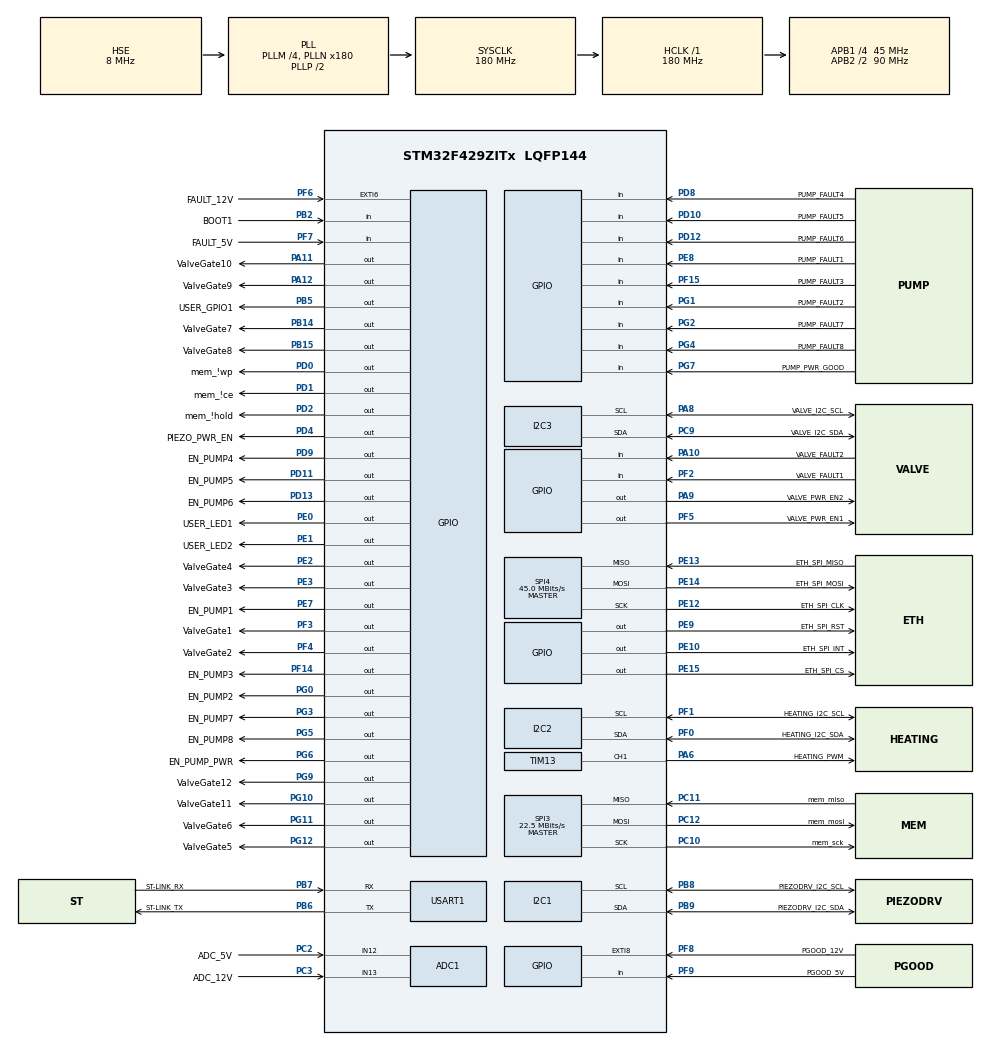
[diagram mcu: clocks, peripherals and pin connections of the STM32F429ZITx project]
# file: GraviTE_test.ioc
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ADC1.Channel-3\#ChannelRegularConversion=ADC_CHANNEL_TEMPSENSOR
ADC1.Channel-4\#ChannelRegularConversion=ADC_CHANNEL_12
ADC1.Channel-5\#ChannelRegularConversion=ADC_CHANNEL_12
ADC1.ContinuousConvMode=ENABLE
ADC1.NbrOfConversion=3
ADC1.NbrOfConversionFlag=1
ADC1.Rank-3\#ChannelRegularConversion=1
ADC1.Rank-4\#ChannelRegularConversion=2
ADC1.Rank-5\#ChannelRegularConversion=3
ADC1.SamplingTime-3\#ChannelRegularConversion=ADC_SAMPLETIME_3CYCLES
ADC1.SamplingTime-4\#ChannelRegularConversion=ADC_SAMPLETIME_3CYCLES
ADC1.SamplingTime-5\#ChannelRegularConversion=ADC_SAMPLETIME_3CYCLES
ADC1.ScanConvMode=ENABLE
ADC1.master=1
Dma.ADC1.0.Direction=DMA_PERIPH_TO_MEMORY
Dma.ADC1.0.FIFOMode=DMA_FIFOMODE_DISABLE
Dma.ADC1.0.Instance=DMA2_Stream0
Dma.ADC1.0.MemDataAlignment=DMA_MDATAALIGN_HALFWORD
Dma.ADC1.0.MemInc=DMA_MINC_ENABLE
Dma.ADC1.0.Mode=DMA_CIRCULAR
Dma.ADC1.0.PeriphDataAlignment=DMA_PDATAALIGN_HALFWORD
Dma.ADC1.0.PeriphInc=DMA_PINC_DISABLE
Dma.ADC1.0.Priority=DMA_PRIORITY_LOW
Dma.Request0=ADC1
Dma.Request1=USART1_RX
Dma.Request2=USART1_TX
Dma.USART1_RX.1.Direction=DMA_PERIPH_TO_MEMORY
Dma.USART1_RX.1.FIFOMode=DMA_FIFOMODE_DISABLE
Dma.USART1_RX.1.Instance=DMA2_Stream2
Dma.USART1_RX.1.MemDataAlignment=DMA_MDATAALIGN_BYTE
Dma.USART1_RX.1.MemInc=DMA_MINC_ENABLE
Dma.USART1_RX.1.Mode=DMA_NORMAL
Dma.USART1_RX.1.PeriphDataAlignment=DMA_PDATAALIGN_BYTE
Dma.USART1_RX.1.PeriphInc=DMA_PINC_DISABLE
Dma.USART1_RX.1.Priority=DMA_PRIORITY_LOW
Dma.USART1_TX.2.Direction=DMA_MEMORY_TO_PERIPH
Dma.USART1_TX.2.FIFOMode=DMA_FIFOMODE_DISABLE
Dma.USART1_TX.2.Instance=DMA2_Stream7
Dma.USART1_TX.2.MemDataAlignment=DMA_MDATAALIGN_BYTE
Dma.USART1_TX.2.MemInc=DMA_MINC_ENABLE
Dma.USART1_TX.2.Mode=DMA_NORMAL
Dma.USART1_TX.2.PeriphDataAlignment=DMA_PDATAALIGN_BYTE
Dma.USART1_TX.2.PeriphInc=DMA_PINC_DISABLE
Dma.USART1_TX.2.Priority=DMA_PRIORITY_LOW
Mcu.Family=STM32F4
Mcu.Name=STM32F429ZITx
Mcu.Package=LQFP144
Mcu.UserConstants=CM,$$_ADC3_IP_HANDLE_$$;PT,$$_SPI1_IP_HANDLE_$$
NVIC.ADC_IRQn=true\:0\:0\:false\:false\:true\:true\:true\:true
NVIC.DMA2_Stream0_IRQn=true\:0\:0\:false\:false\:true\:false\:true\:true
NVIC.DMA2_Stream2_IRQn=true\:0\:0\:false\:false\:true\:false\:true\:true
NVIC.DMA2_Stream7_IRQn=true\:0\:0\:false\:false\:true\:false\:true\:true
NVIC.EXTI9_5_IRQn=true\:0\:0\:false\:false\:true\:true\:true\:true
NVIC.I2C2_EV_IRQn=true\:0\:0\:false\:false\:true\:true\:true\:true
NVIC.I2C3_EV_IRQn=true\:0\:0\:false\:false\:true\:true\:true\:true
NVIC.PriorityGroup=NVIC_PRIORITYGROUP_4
NVIC.TIM1_UP_TIM10_IRQn=true\:15\:0\:false\:false\:true\:false\:true\:true
NVIC.TimeBase=TIM1_UP_TIM10_IRQn
NVIC.TimeBaseIP=TIM1
PA10.GPIO_Label=VALVE_FAULT2
PA10.Signal=GPIO_Input
PA11.GPIO_Label=ValveGate10
PA11.Signal=GPIO_Output
PA12.GPIO_Label=ValveGate9
PA12.Signal=GPIO_Output
PA13.Mode=JTAG_5_pins
PA13.Signal=SYS_JTMS-SWDIO
PA14.Mode=JTAG_5_pins
PA14.Signal=SYS_JTCK-SWCLK
PA15.Mode=JTAG_5_pins
PA15.Signal=SYS_JTDI
PA6.GPIO_Label=HEATING_PWM
PA6.Signal=S_TIM13_CH1
PA8.GPIO_Label=VALVE_I2C_SCL
PA8.Mode=I2C
PA8.Signal=I2C3_SCL
PA9.GPIO_Label=VALVE_PWR_EN2
PA9.Signal=GPIO_Output
PB14.GPIO_Label=ValveGate7
PB14.Signal=GPIO_Output
PB15.GPIO_Label=ValveGate8
PB15.Signal=GPIO_Output
PB2/BOOT1.GPIO_Label=BOOT1
PB2/BOOT1.Signal=GPIO_Input
PB3.Mode=JTAG_5_pins
PB3.Signal=SYS_JTDO-SWO
PB4.Mode=JTAG_5_pins
PB4.Signal=SYS_JTRST
PB5.GPIO_Label=USER_GPIO1
PB5.Signal=GPIO_Output
PB6.GPIO_Label=ST-LINK_TX
PB6.Mode=Asynchronous
PB6.Signal=USART1_TX
PB7.GPIO_Label=ST-LINK_RX
PB7.Mode=Asynchronous
PB7.Signal=USART1_RX
PB8.GPIO_Label=PIEZODRV_I2C_SCL
PB8.Mode=I2C
PB8.Signal=I2C1_SCL
PB9.GPIO_Label=PIEZODRV_I2C_SDA
PB9.Mode=I2C
PB9.Signal=I2C1_SDA
PC10.GPIO_Label=mem_sck
PC10.Mode=Full_Duplex_Master
PC10.Signal=SPI3_SCK
PC11.GPIO_Label=mem_miso
PC11.Mode=Full_Duplex_Master
PC11.Signal=SPI3_MISO
PC12.GPIO_Label=mem_mosi
PC12.Mode=Full_Duplex_Master
PC12.Signal=SPI3_MOSI
PC14/OSC32_IN.Signal=RCC_OSC32_IN
PC2.GPIO_Label=ADC_5V
PC2.Signal=ADCx_IN12
PC3.GPIO_Label=ADC_12V
PC3.Signal=ADCx_IN13
PC9.GPIO_Label=VALVE_I2C_SDA
PC9.Mode=I2C
PC9.Signal=I2C3_SDA
PD0.GPIO_Label=mem_\!wp
PD0.Signal=GPIO_Output
PD1.GPIO_Label=mem_\!ce
PD1.Signal=GPIO_Output
PD10.GPIO_Label=PUMP_FAULT5
PD10.Signal=GPIO_Input
PD11.GPIO_Label=EN_PUMP5
PD11.Signal=GPIO_Output
PD12.GPIO_Label=PUMP_FAULT6
PD12.Signal=GPIO_Input
PD13.GPIO_Label=EN_PUMP6
PD13.Signal=GPIO_Output
PD2.GPIO_Label=mem_\!hold
PD2.Signal=GPIO_Output
PD4.GPIO_Label=PIEZO_PWR_EN
PD4.Signal=GPIO_Output
PD8.GPIO_Label=PUMP_FAULT4
PD8.Signal=GPIO_Input
PD9.GPIO_Label=EN_PUMP4
PD9.Signal=GPIO_Output
PE0.GPIO_Label=USER_LED1
PE0.Signal=GPIO_Output
PE1.GPIO_Label=USER_LED2
PE1.Signal=GPIO_Output
PE10.GPIO_Label=ETH_SPI_INT
PE10.Signal=GPIO_Output
PE12.GPIO_Label=ETH_SPI_CLK
PE12.Mode=Full_Duplex_Master
PE12.Signal=SPI4_SCK
PE13.GPIO_Label=ETH_SPI_MISO
PE13.Mode=Full_Duplex_Master
PE13.Signal=SPI4_MISO
PE14.GPIO_Label=ETH_SPI_MOSI
PE14.Mode=Full_Duplex_Master
PE14.Signal=SPI4_MOSI
PE15.GPIO_Label=ETH_SPI_CS
PE15.Signal=GPIO_Output
PE2.GPIO_Label=ValveGate4
PE2.Signal=GPIO_Output
PE3.GPIO_Label=ValveGate3
PE3.Signal=GPIO_Output
PE7.GPIO_Label=EN_PUMP1
PE7.Signal=GPIO_Output
PE8.GPIO_Label=PUMP_FAULT1
PE8.Signal=GPIO_Input
PE9.GPIO_Label=ETH_SPI_RST
PE9.Signal=GPIO_Output
PF0.GPIO_Label=HEATING_I2C_SDA
PF0.Mode=I2C
PF0.Signal=I2C2_SDA
PF1.GPIO_Label=HEATING_I2C_SCL
PF1.Mode=I2C
PF1.Signal=I2C2_SCL
PF14.GPIO_Label=EN_PUMP3
PF14.Signal=GPIO_Output
PF15.GPIO_Label=PUMP_FAULT3
PF15.Signal=GPIO_Input
PF2.GPIO_Label=VALVE_FAULT1
PF2.Signal=GPIO_Input
PF3.GPIO_Label=ValveGate1
PF3.Signal=GPIO_Output
PF4.GPIO_Label=ValveGate2
PF4.Signal=GPIO_Output
PF5.GPIO_Label=VALVE_PWR_EN1
PF5.Signal=GPIO_Output
PF6.GPIO_Label=FAULT_12V
PF6.GPIO_ModeDefaultEXTI=GPIO_MODE_IT_FALLING
PF6.Signal=GPXTI6
PF7.GPIO_Label=FAULT_5V
PF7.Signal=GPIO_Input
PF8.GPIO_Label=PGOOD_12V
PF8.Signal=GPXTI8
PF9.GPIO_Label=PGOOD_5V
PF9.Signal=GPIO_Input
PG0.GPIO_Label=EN_PUMP2
PG0.Signal=GPIO_Output
PG1.GPIO_Label=PUMP_FAULT2
PG1.Signal=GPIO_Input
PG10.GPIO_Label=ValveGate11
PG10.Signal=GPIO_Output
PG11.GPIO_Label=ValveGate6
PG11.Signal=GPIO_Output
PG12.GPIO_Label=ValveGate5
PG12.Signal=GPIO_Output
PG2.GPIO_Label=PUMP_FAULT7
PG2.Signal=GPIO_Input
PG3.GPIO_Label=EN_PUMP7
PG3.Signal=GPIO_Output
PG4.GPIO_Label=PUMP_FAULT8
PG4.Signal=GPIO_Input
PG5.GPIO_Label=EN_PUMP8
PG5.Signal=GPIO_Output
PG6.GPIO_Label=EN_PUMP_PWR
PG6.Signal=GPIO_Output
PG7.GPIO_Label=PUMP_PWR_GOOD
PG7.Signal=GPIO_Input
PG9.GPIO_Label=ValveGate12
PG9.Signal=GPIO_Output
PH0/OSC_IN.Mode=HSE-External-Oscillator
PH0/OSC_IN.Signal=RCC_OSC_IN
PH1/OSC_OUT.Mode=HSE-External-Oscillator
PH1/OSC_OUT.Signal=RCC_OSC_OUT
ProjectManager.HeapSize=0x200
ProjectManager.StackSize=0x400
ProjectManager.TargetToolchain=CMake
RCC.48MHZClocksFreq_Value=51428571.428571425
RCC.AHBFreq_Value=180000000
RCC.APB1CLKDivider=RCC_HCLK_DIV4
RCC.APB1Freq_Value=45000000
RCC.APB1TimFreq_Value=90000000
RCC.APB2CLKDivider=RCC_HCLK_DIV2
RCC.APB2Freq_Value=90000000
RCC.APB2TimFreq_Value=180000000
RCC.CortexFreq_Value=180000000
RCC.HCLKFreq_Value=180000000
RCC.HSE_VALUE=8000000
RCC.HSI_VALUE=16000000
RCC.LSE_VALUE=32768
RCC.PLLM=4
RCC.PLLMUL=RCC_PLL_MUL9
RCC.PLLN=180
RCC.PLLQ=7
RCC.PLLSourceVirtual=RCC_PLLSOURCE_HSE
RCC.PRESCALERUSB=RCC_USBCLKSOURCE_PLL_DIV1_5
RCC.SYSCLKFreq_VALUE=180000000
RCC.SYSCLKSource=RCC_SYSCLKSOURCE_PLLCLK
RCC.SYSCLKSourceVirtual=RCC_SYSCLKSOURCE_PLLCLK
RCC.USBFreq_Value=48000000
RCC.VCOOutputFreq_Value=360000000
SH.ADCx_IN12.0=ADC1_IN12,IN12
SH.ADCx_IN13.0=ADC1_IN13,IN13
SH.S_TIM13_CH1.0=TIM13_CH1,PWM Generation1 CH1
SPI3.CalculateBaudRate=22.5 MBits/s
SPI3.Direction=SPI_DIRECTION_2LINES
SPI3.Mode=SPI_MODE_MASTER
SPI3.VirtualType=VM_MASTER
SPI4.CalculateBaudRate=45.0 MBits/s
SPI4.Direction=SPI_DIRECTION_2LINES
SPI4.Mode=SPI_MODE_MASTER
SPI4.VirtualType=VM_MASTER
TIM13.Channel=TIM_CHANNEL_1
TIM13.Period=9999
TIM13.Prescaler=1799
USART1.VirtualMode=VM_ASYNC
VP_ADC1_TempSens_Input.Mode=IN-TempSens
VP_RTC_VS_RTC_Activate.Mode=RTC_Enabled
VP_SYS_VS_tim1.Mode=TIM1
VP_TIM13_VS_ClockSourceINT.Mode=Enable_Timer
board=NUCLEO-F429ZI

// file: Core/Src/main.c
/* USER CODE BEGIN Header */
/**
  ******************************************************************************
  * @file           : main.c
  * @brief          : Main program body
  ******************************************************************************
  * @attention
  *
  * Copyright (c) 2026 STMicroelectronics.
  * All rights reserved.
  *
  * This software is licensed under terms that can be found in the LICENSE file
  * in the root directory of this software component.
  * If no LICENSE file comes with this software, it is provided AS-IS.
  *
  ******************************************************************************
  */
/* USER CODE END Header */
#include "main.h"
#include "adc.h"
#include "dma.h"
#include "i2c.h"
#include "rtc.h"
#include "spi.h"
#include "tim.h"
#include "usart.h"
#include "gpio.h"

/* USER CODE BEGIN PTD */
typedef struct {
  GPIO_TypeDef *port;
  uint16_t pin;
} Act_Config;
/* USER CODE END PTD */

/* USER CODE BEGIN PD */
#define MAX_PERIPHERAL_CODE 0x18
/* USER CODE END PD */

/* USER CODE BEGIN PV */
static uint8_t Rx_buffer;

const Act_Config peripheral_map[] = {
    // Valves
    {NULL, 0}, // 0x00
    {ValveGate1_GPIO_Port, ValveGate1_Pin}, // 0x01
    {ValveGate2_GPIO_Port, ValveGate2_Pin}, // 0x02
    {ValveGate3_GPIO_Port, ValveGate3_Pin}, // 0x03
    {ValveGate4_GPIO_Port, ValveGate4_Pin}, // 0x04
    {ValveGate5_GPIO_Port, ValveGate5_Pin}, // 0x05
    {ValveGate6_GPIO_Port, ValveGate6_Pin}, // 0x06
    {ValveGate7_GPIO_Port, ValveGate7_Pin}, // 0x07
    {ValveGate8_GPIO_Port, ValveGate8_Pin}, // 0x08
    {ValveGate9_GPIO_Port, ValveGate9_Pin}, // 0x09
    {ValveGate10_GPIO_Port, ValveGate10_Pin}, // 0x0A
    {ValveGate11_GPIO_Port, ValveGate11_Pin}, // 0x0B
    {ValveGate12_GPIO_Port, ValveGate12_Pin}, // 0x0C
    // Pizeo pumps
    {NULL, 0}, // 0x0D
    {NULL, 0}, // 0x0E
    {NULL, 0}, // 0x0F
    {NULL, 0}, // 0x10
    // Peristaltic pumps
    {EN_PUMP1_GPIO_Port,  EN_PUMP1_Pin},  // 0x11
    {EN_PUMP2_GPIO_Port,  EN_PUMP2_Pin},  // 0x12
    {EN_PUMP3_GPIO_Port,  EN_PUMP3_Pin},  // 0x13
    {EN_PUMP4_GPIO_Port,  EN_PUMP4_Pin},  // 0x14
    {EN_PUMP5_GPIO_Port,  EN_PUMP5_Pin},  // 0x15
    {EN_PUMP6_GPIO_Port,  EN_PUMP6_Pin},  // 0x16
    {EN_PUMP7_GPIO_Port,  EN_PUMP7_Pin},  // 0x17
    {EN_PUMP8_GPIO_Port,  EN_PUMP8_Pin},  // 0x18
};
/* USER CODE END PV */

void SystemClock_Config(void);

int main(void)
{

  /* MCU Configuration--------------------------------------------------------*/

  /* Reset of all peripherals, Initializes the Flash interface and the Systick. */
  HAL_Init();

  /* Configure the system clock */
  SystemClock_Config();

  /* Initialize all configured peripherals */
  MX_GPIO_Init();
  MX_DMA_Init();
  MX_ADC1_Init();
  MX_SPI3_Init();
  MX_I2C1_Init();
  MX_I2C2_Init();
  MX_I2C3_Init();
  MX_USART1_UART_Init();
  MX_RTC_Init();
  MX_SPI4_Init();
  MX_TIM13_Init();
  /* USER CODE BEGIN 2 */
  HAL_UART_Receive_DMA(&huart1, &Rx_buffer, 1);

  HAL_GPIO_WritePin(EN_PUMP_PWR_GPIO_Port, EN_PUMP_PWR_Pin, 1);
  // HAL_GPIO_WritePin(PIEZO_PWR_EN_GPIO_Port, PIEZO_PWR_EN_Pin, 1);
  HAL_GPIO_WritePin(VALVE_PWR_EN1_GPIO_Port, VALVE_PWR_EN1_Pin, 1);
  HAL_GPIO_WritePin(VALVE_PWR_EN2_GPIO_Port, VALVE_PWR_EN2_Pin, 1);
  /* USER CODE END 2 */

  /* Infinite loop */
  while (1)
  {

  }
}

void SystemClock_Config(void)
{
  RCC_OscInitTypeDef RCC_OscInitStruct = {0};
  RCC_ClkInitTypeDef RCC_ClkInitStruct = {0};

  /** Configure the main internal regulator output voltage
  */
  __HAL_RCC_PWR_CLK_ENABLE();
  __HAL_PWR_VOLTAGESCALING_CONFIG(PWR_REGULATOR_VOLTAGE_SCALE1);

  /** Initializes the RCC Oscillators according to the specified parameters
  * in the RCC_OscInitTypeDef structure.
  */
  RCC_OscInitStruct.OscillatorType = RCC_OSCILLATORTYPE_LSI|RCC_OSCILLATORTYPE_HSE;
  RCC_OscInitStruct.HSEState = RCC_HSE_ON;
  RCC_OscInitStruct.LSIState = RCC_LSI_ON;
  RCC_OscInitStruct.PLL.PLLState = RCC_PLL_ON;
  RCC_OscInitStruct.PLL.PLLSource = RCC_PLLSOURCE_HSE;
  RCC_OscInitStruct.PLL.PLLM = 4;
  RCC_OscInitStruct.PLL.PLLN = 180;
  RCC_OscInitStruct.PLL.PLLP = RCC_PLLP_DIV2;
  RCC_OscInitStruct.PLL.PLLQ = 7;
  if (HAL_RCC_OscConfig(&RCC_OscInitStruct) != HAL_OK)
  {
    Error_Handler();
  }

  /** Activate the Over-Drive mode
  */
  if (HAL_PWREx_EnableOverDrive() != HAL_OK)
  {
    Error_Handler();
  }

  /** Initializes the CPU, AHB and APB buses clocks
  */
  RCC_ClkInitStruct.ClockType = RCC_CLOCKTYPE_HCLK|RCC_CLOCKTYPE_SYSCLK
                              |RCC_CLOCKTYPE_PCLK1|RCC_CLOCKTYPE_PCLK2;
  RCC_ClkInitStruct.SYSCLKSource = RCC_SYSCLKSOURCE_PLLCLK;
  RCC_ClkInitStruct.AHBCLKDivider = RCC_SYSCLK_DIV1;
  RCC_ClkInitStruct.APB1CLKDivider = RCC_HCLK_DIV4;
  RCC_ClkInitStruct.APB2CLKDivider = RCC_HCLK_DIV2;

  if (HAL_RCC_ClockConfig(&RCC_ClkInitStruct, FLASH_LATENCY_5) != HAL_OK)
  {
    Error_Handler();
  }
}

/* USER CODE BEGIN 4 */
void HAL_UART_RxCpltCallback(UART_HandleTypeDef *huart) {
  if (huart->Instance == USART1) {
    uint16_t data = Rx_buffer;

    if (data <= MAX_PERIPHERAL_CODE) HAL_GPIO_TogglePin(peripheral_map[data].port, peripheral_map[data].pin);
    else {
      uint8_t error_flag = 0xFF;
      HAL_UART_Transmit(&huart1, &error_flag, 1, 100);
    }

    HAL_UART_Transmit(&huart1, &Rx_buffer, 1, 100);

    HAL_UART_Receive_DMA(&huart1, &Rx_buffer, 1);
  }
}
/* USER CODE END 4 */

void HAL_TIM_PeriodElapsedCallback(TIM_HandleTypeDef *htim)
{
  if (htim->Instance == TIM1) {
    HAL_IncTick();
  }
}

void Error_Handler(void)
{
  __disable_irq();
  while (1)
  {
  }
}
